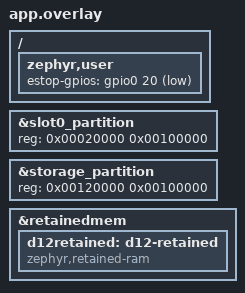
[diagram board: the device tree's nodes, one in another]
/*
 * Copyright (c) 2026 Tessera Project
 * SPDX-License-Identifier: Apache-2.0
 *
 * r14 estop 绑定（owner 裁决 GPIO20=J4-31；机制与物理沿翻译见
 * drivers.c 注释）+ r16 板级 flash 布局（storage 1MB@0x120000——
 * D12 红线断言逼出 RAM 镜像数组债后切 flash 后端）。
 */
/ {
	zephyr,user {
		estop-gpios = <&gpio0 20 (GPIO_ACTIVE_LOW | GPIO_PULL_UP)>;
	};
};

&slot0_partition {
	reg = <0x00020000 0x00100000>;
};

&storage_partition {
	reg = <0x00120000 0x00100000>;
};

&retainedmem {
	/* r16 storm 计数：LP 域 retained RAM（跨 soft/WDT 复位保留、POR
	 * 清=天然风暴窗出；dram0.noinit 实证为 flash 装载恢复段不可用）。 */
	status = "okay";
	ranges;
	#address-cells = <1>;
	#size-cells = <1>;

	d12retained: d12-retained {
		compatible = "zephyr,retained-ram";
		status = "okay";
	};
};
